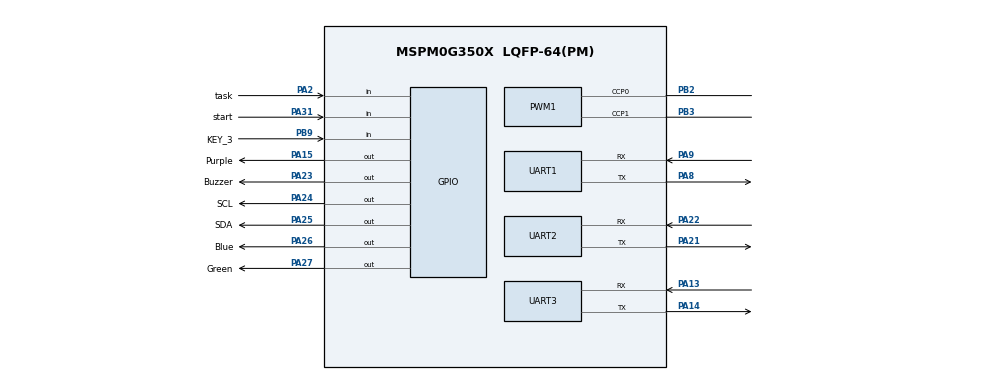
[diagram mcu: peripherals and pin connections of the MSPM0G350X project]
/**
 * @cliArgs --device "MSPM0G350X" --part "Default" --package "LQFP-64(PM)" --product "mspm0_sdk@2.03.00.07"
 * @versions {"tool":"1.22.0+3893"}
 */

/**
 * Import the modules used in this configuration.
 */
const GPIO    = scripting.addModule("/ti/driverlib/GPIO", {}, false);
const GPIO1   = GPIO.addInstance();
const GPIO2   = GPIO.addInstance();
const GPIO3   = GPIO.addInstance();
const GPIO4   = GPIO.addInstance();
const GPIO5   = GPIO.addInstance();
const PWM     = scripting.addModule("/ti/driverlib/PWM", {}, false);
const PWM1    = PWM.addInstance();
const SYSCTL  = scripting.addModule("/ti/driverlib/SYSCTL");
const SYSTICK = scripting.addModule("/ti/driverlib/SYSTICK");
const TIMER   = scripting.addModule("/ti/driverlib/TIMER", {}, false);
const TIMER1  = TIMER.addInstance();
const TIMER2  = TIMER.addInstance();
const UART    = scripting.addModule("/ti/driverlib/UART", {}, false);
const UART1   = UART.addInstance();
const UART2   = UART.addInstance();
const UART3   = UART.addInstance();

/**
 * Write custom configuration values to the imported modules.
 */
const divider6       = system.clockTree["PLL_CLK2X_DIV"];
divider6.divideValue = 4;

const divider7       = system.clockTree["PLL_PDIV"];
divider7.divideValue = 4;

const divider9       = system.clockTree["UDIV"];
divider9.divideValue = 2;

const gate7  = system.clockTree["MFCLKGATE"];
gate7.enable = true;

const multiplier2         = system.clockTree["PLL_QDIV"];
multiplier2.multiplyValue = 20;

const mux4       = system.clockTree["EXHFMUX"];
mux4.inputSelect = "EXHFMUX_XTAL";

const mux8       = system.clockTree["HSCLKMUX"];
mux8.inputSelect = "HSCLKMUX_SYSPLL2X";

const pinFunction4     = system.clockTree["HFXT"];
pinFunction4.inputFreq = 40;
pinFunction4.enable    = true;

GPIO1.port                               = "PORTA";
GPIO1.$name                              = "LED";
GPIO1.associatedPins.create(3);
GPIO1.associatedPins[0].internalResistor = "PULL_DOWN";
GPIO1.associatedPins[0].$name            = "Blue";
GPIO1.associatedPins[0].assignedPin      = "26";
GPIO1.associatedPins[0].pin.$assign      = "PA26";
GPIO1.associatedPins[1].$name            = "Green";
GPIO1.associatedPins[1].assignedPin      = "27";
GPIO1.associatedPins[1].pin.$assign      = "PA27";
GPIO1.associatedPins[2].$name            = "Purple";
GPIO1.associatedPins[2].assignedPin      = "15";
GPIO1.associatedPins[2].pin.$assign      = "PA15";

const Board = scripting.addModule("/ti/driverlib/Board", {}, false);

GPIO2.port                               = "PORTA";
GPIO2.$name                              = "KEY";
GPIO2.associatedPins.create(2);
GPIO2.associatedPins[0].direction        = "INPUT";
GPIO2.associatedPins[0].$name            = "task";
GPIO2.associatedPins[0].internalResistor = "PULL_UP";
GPIO2.associatedPins[0].inputFilter      = "8_CYCLES";
GPIO2.associatedPins[0].assignedPin      = "02";
GPIO2.associatedPins[0].pin.$assign      = "PA2";
GPIO2.associatedPins[1].direction        = "INPUT";
GPIO2.associatedPins[1].$name            = "start";
GPIO2.associatedPins[1].internalResistor = "PULL_UP";
GPIO2.associatedPins[1].inputFilter      = "8_CYCLES";
GPIO2.associatedPins[1].assignedPin      = "31";
GPIO2.associatedPins[1].pin.$assign      = "PA31";

GPIO3.port                           = "PORTA";
GPIO3.$name                          = "BUZZER";
GPIO3.associatedPins[0].$name        = "Buzzer";
GPIO3.associatedPins[0].assignedPin  = "23";
GPIO3.associatedPins[0].initialValue = "SET";
GPIO3.associatedPins[0].pin.$assign  = "PA23";

GPIO4.$name                         = "KEY3";
GPIO4.port                          = "PORTB";
GPIO4.associatedPins[0].$name       = "KEY_3";
GPIO4.associatedPins[0].direction   = "INPUT";
GPIO4.associatedPins[0].assignedPin = "9";
GPIO4.associatedPins[0].pin.$assign = "PB9";

GPIO5.$name                          = "OLED";
GPIO5.port                           = "PORTA";
GPIO5.associatedPins.create(2);
GPIO5.associatedPins[0].$name        = "SCL";
GPIO5.associatedPins[0].initialValue = "SET";
GPIO5.associatedPins[0].assignedPin  = "24";
GPIO5.associatedPins[0].pin.$assign  = "PA24";
GPIO5.associatedPins[1].$name        = "SDA";
GPIO5.associatedPins[1].initialValue = "SET";
GPIO5.associatedPins[1].assignedPin  = "25";
GPIO5.associatedPins[1].pin.$assign  = "PA25";

PWM1.$name                              = "PWM";
PWM1.clockDivider                       = 8;
PWM1.pwmMode                            = "EDGE_ALIGN_UP";
PWM1.timerStartTimer                    = true;
PWM1.clockPrescale                      = 4;
PWM1.peripheral.$assign                 = "TIMG6";
PWM1.peripheral.ccp0Pin.$assign         = "PB2";
PWM1.peripheral.ccp1Pin.$assign         = "PB3";
PWM1.PWM_CHANNEL_0.$name                = "ti_driverlib_pwm_PWMTimerCC0";
PWM1.PWM_CHANNEL_1.$name                = "ti_driverlib_pwm_PWMTimerCC1";
PWM1.ccp0PinConfig.direction            = scripting.forceWrite("OUTPUT");
PWM1.ccp0PinConfig.hideOutputInversion  = scripting.forceWrite(false);
PWM1.ccp0PinConfig.onlyInternalResistor = scripting.forceWrite(false);
PWM1.ccp0PinConfig.passedPeripheralType = scripting.forceWrite("Digital");
PWM1.ccp0PinConfig.$name                = "ti_driverlib_gpio_GPIOPinGeneric2";
PWM1.ccp1PinConfig.direction            = scripting.forceWrite("OUTPUT");
PWM1.ccp1PinConfig.hideOutputInversion  = scripting.forceWrite(false);
PWM1.ccp1PinConfig.onlyInternalResistor = scripting.forceWrite(false);
PWM1.ccp1PinConfig.passedPeripheralType = scripting.forceWrite("Digital");
PWM1.ccp1PinConfig.$name                = "ti_driverlib_gpio_GPIOPinGeneric3";

SYSCTL.forceDefaultClkConfig = true;
SYSCTL.clockTreeEn           = true;

SYSTICK.periodEnable      = true;
SYSTICK.systickEnable     = true;
SYSTICK.interruptPriority = "0";
SYSTICK.period            = 32;

TIMER1.$name              = "TIMER_0";
TIMER1.timerClkDiv        = 8;
TIMER1.timerClkPrescale   = 100;
TIMER1.timerMode          = "PERIODIC";
TIMER1.interrupts         = ["ZERO"];
TIMER1.timerStartTimer    = true;
TIMER1.timerPeriod        = "10ms";
TIMER1.interruptPriority  = "0";
TIMER1.peripheral.$assign = "TIMA0";

TIMER2.$name              = "TIMER_1";
TIMER2.timerStartTimer    = true;
TIMER2.timerMode          = "PERIODIC";
TIMER2.timerClkDiv        = 8;
TIMER2.timerClkPrescale   = 100;
TIMER2.interrupts         = ["LOAD"];
TIMER2.interruptPriority  = "1";
TIMER2.timerPeriod        = "10ms";
TIMER2.peripheral.$assign = "TIMG0";

UART1.$name                            = "UART_1";
UART1.targetBaudRate                   = 115200;
UART1.interruptPriority                = "0";
UART1.enabledInterrupts                = ["RX"];
UART1.peripheral.$assign               = "UART1";
UART1.peripheral.rxPin.$assign         = "PA9";
UART1.peripheral.txPin.$assign         = "PA8";
UART1.txPinConfig.direction            = scripting.forceWrite("OUTPUT");
UART1.txPinConfig.hideOutputInversion  = scripting.forceWrite(false);
UART1.txPinConfig.onlyInternalResistor = scripting.forceWrite(false);
UART1.txPinConfig.passedPeripheralType = scripting.forceWrite("Digital");
UART1.txPinConfig.$name                = "ti_driverlib_gpio_GPIOPinGeneric0";
UART1.txPinConfig.internalResistor     = "PULL_UP";
UART1.rxPinConfig.hideOutputInversion  = scripting.forceWrite(false);
UART1.rxPinConfig.onlyInternalResistor = scripting.forceWrite(false);
UART1.rxPinConfig.passedPeripheralType = scripting.forceWrite("Digital");
UART1.rxPinConfig.$name                = "ti_driverlib_gpio_GPIOPinGeneric1";
UART1.rxPinConfig.internalResistor     = "PULL_UP";

UART2.$name                            = "UART_2";
UART2.targetBaudRate                   = 115200;
UART2.peripheral.$assign               = "UART2";
UART2.peripheral.rxPin.$assign         = "PA22";
UART2.peripheral.txPin.$assign         = "PA21";
UART2.txPinConfig.direction            = scripting.forceWrite("OUTPUT");
UART2.txPinConfig.hideOutputInversion  = scripting.forceWrite(false);
UART2.txPinConfig.onlyInternalResistor = scripting.forceWrite(false);
UART2.txPinConfig.passedPeripheralType = scripting.forceWrite("Digital");
UART2.txPinConfig.$name                = "ti_driverlib_gpio_GPIOPinGeneric6";
UART2.txPinConfig.enableConfig         = true;
UART2.txPinConfig.internalResistor     = "PULL_UP";
UART2.rxPinConfig.hideOutputInversion  = scripting.forceWrite(false);
UART2.rxPinConfig.onlyInternalResistor = scripting.forceWrite(false);
UART2.rxPinConfig.passedPeripheralType = scripting.forceWrite("Digital");
UART2.rxPinConfig.$name                = "ti_driverlib_gpio_GPIOPinGeneric7";
UART2.rxPinConfig.enableConfig         = true;
UART2.rxPinConfig.internalResistor     = "PULL_UP";

UART3.$name                            = "UART_3";
UART3.targetBaudRate                   = 115200;
UART3.peripheral.$assign               = "UART3";
UART3.peripheral.rxPin.$assign         = "PA13";
UART3.peripheral.txPin.$assign         = "PA14";
UART3.txPinConfig.direction            = scripting.forceWrite("OUTPUT");
UART3.txPinConfig.hideOutputInversion  = scripting.forceWrite(false);
UART3.txPinConfig.onlyInternalResistor = scripting.forceWrite(false);
UART3.txPinConfig.passedPeripheralType = scripting.forceWrite("Digital");
UART3.txPinConfig.$name                = "ti_driverlib_gpio_GPIOPinGeneric8";
UART3.txPinConfig.enableConfig         = true;
UART3.txPinConfig.internalResistor     = "PULL_UP";
UART3.rxPinConfig.hideOutputInversion  = scripting.forceWrite(false);
UART3.rxPinConfig.onlyInternalResistor = scripting.forceWrite(false);
UART3.rxPinConfig.passedPeripheralType = scripting.forceWrite("Digital");
UART3.rxPinConfig.$name                = "ti_driverlib_gpio_GPIOPinGeneric9";
UART3.rxPinConfig.enableConfig         = true;
UART3.rxPinConfig.internalResistor     = "PULL_UP";

/**
 * Pinmux solution for unlocked pins/peripherals. This ensures that minor changes to the automatic solver in a future
 * version of the tool will not impact the pinmux you originally saw.  These lines can be completely deleted in order to
 * re-solve from scratch.
 */
pinFunction4.peripheral.$suggestSolution           = "SYSCTL";
pinFunction4.peripheral.hfxInPin.$suggestSolution  = "PA5";
pinFunction4.peripheral.hfxOutPin.$suggestSolution = "PA6";
Board.peripheral.$suggestSolution                  = "DEBUGSS";
Board.peripheral.swclkPin.$suggestSolution         = "PA20";
Board.peripheral.swdioPin.$suggestSolution         = "PA19";
